# PIC32CM1216LS00032 device description
Architecture: CORTEX-M23; Family: PIC32CM; Series: PIC32CMLS00
Registers are 32-bit, read-write, reset 0x0 unless marked. A register's access mark holds for its fields unless they carry their own. Offsets are from the block's base; [hi:lo] are bit positions; 'fields as' and 'values as' point back to an identical list.

## OSC32KCTRL — 32k Oscillators Control
Instances: OSC32KCTRL 0x40001400
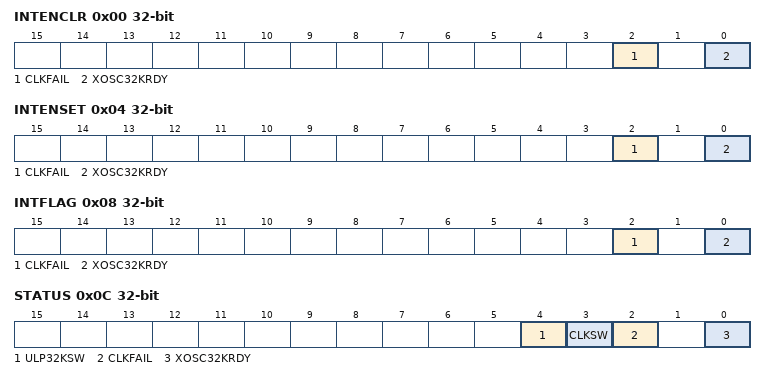
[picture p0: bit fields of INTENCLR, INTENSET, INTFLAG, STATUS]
0x00 INTENCLR (atomic clear) — Interrupt Enable Clear
  [2] CLKFAIL — XOSC32K Clock Failure Detector Interrupt Enable
  [0] XOSC32KRDY — XOSC32K Ready Interrupt Enable
0x04 INTENSET (atomic set) — Interrupt Enable Set
  fields as INTENCLR
0x08 INTFLAG (atomic clear) — Interrupt Flag Status and Clear
  [2] CLKFAIL — XOSC32K Clock Failure Detector
  [0] XOSC32KRDY — XOSC32K Ready
0x0C STATUS ro — Power and Clocks Status
  [4] ULP32KSW — OSCULP32K Clock Switch
  [3] CLKSW — XOSC32K Clock switch
  [2] CLKFAIL — XOSC32K Clock Failure Detector
  [0] XOSC32KRDY — XOSC32K Ready
0x10 RTCCTRL 8-bit — RTC Clock Selection
  [2:0] RTCSEL
    0=ULP1K (1.024kHz from 32kHz internal ULP oscillator); 1=ULP32K (32.768kHz from 32kHz internal ULP oscillator); 4=XOSC1K (1.024kHz from 32.768kHz external crystal oscillator); 5=XOSC32K (32.768kHz from 32.768kHz external crystal oscillator)
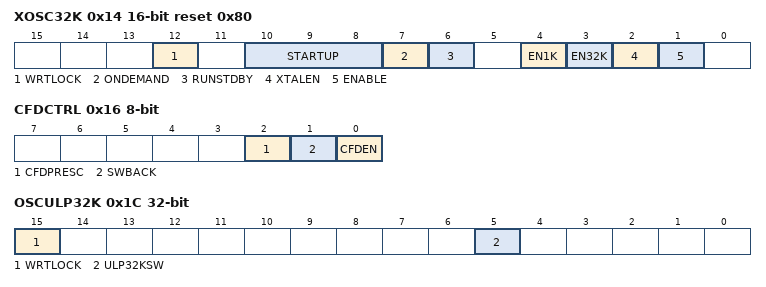
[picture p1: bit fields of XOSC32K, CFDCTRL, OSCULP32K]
0x14 XOSC32K 16-bit reset 0x80 — 32kHz External Crystal Oscillator (XOSC32K) Control
  [12] WRTLOCK — Write Lock
  [10:8] STARTUP — Oscillator Start-Up Time
    0=CYCLE2048 (62.5 ms); 1=CYCLE4096 (125 ms); 2=CYCLE16384 (500 ms); 3=CYCLE32768 (1000 ms); 4=CYCLE65536 (2000 ms); 5=CYCLE131072 (4000 ms); 6=CYCLE262144 (8000 ms)
  [7] ONDEMAND — On Demand Control
  [6] RUNSTDBY — Run in Standby
  [4] EN1K — 1kHz Output Enable
  [3] EN32K — 32kHz Output Enable
  [2] XTALEN — Crystal Oscillator Enable
  [1] ENABLE — Oscillator Enable
0x16 CFDCTRL 8-bit — Clock Failure Detector Control
  [2] CFDPRESC — Clock Failure Detector Prescaler
  [1] SWBACK — Clock Switch Back Enable
  [0] CFDEN — Clock Failure Detector Enable
0x17 EVCTRL 8-bit — Event Control
  [0] CFDEO — Clock Failure Detector Event Output Enable
0x1C OSCULP32K — 32kHz Ultra Low Power Internal Oscillator (OSCULP32K) Control
  [15] WRTLOCK — Write Lock
  [5] ULP32KSW — OSCULP32K Clock Switch Enable

## PM — Power Manager
Instances: PM 0x40000400
0x01 SLEEPCFG 8-bit reset 0x2 — Sleep Configuration
  [2:0] SLEEPMODE
    2=IDLE (CPU, AHBx, and APBx clocks are OFF); 4=STANDBY (ALL clocks are OFF, unless requested by sleepwalking peripheral); 6=OFF (All power domains are powered OFF)
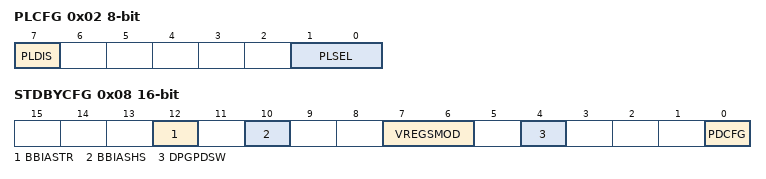
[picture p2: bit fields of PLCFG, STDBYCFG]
0x02 PLCFG 8-bit — Performance Level Configuration
  [7] PLDIS — Performance Level Disable
  [1:0] PLSEL — Performance Level Select
    0=PL0 (Performance Level 0); 2=PL2 (Performance Level 2)
0x03 PWCFG 8-bit — Power Configuration
  [1:0] RAMPSWC — RAM Power Switch Configuration
    0=SIZE0 (SRAM Retention: 64KB (512KB Flash), 32KB (256KB Flash), 16KB (128KB Flash)); 1=SIZE1 (SRAM Retention: 48KB (512KB Flash), 32KB (256KB Flash), 12KB (128KB Flash)); 2=SIZE2 (SRAM Retention: 32KB (512KB Flash), 32KB (256KB Flash), 8KB (128KB Flash)); 3=SIZE3 (SRAM Retention: 16KB (512KB Flash), 16KB (256KB Flash), 4KB (128KB Flash))
0x04 INTENCLR 8-bit (atomic clear) — Interrupt Enable Clear
  [0] PLRDY — Performance Level Interrupt Enable
0x05 INTENSET 8-bit (atomic set) — Interrupt Enable Set
  [0] PLRDY — Performance Level Ready interrupt Enable
0x06 INTFLAG 8-bit (atomic clear) — Interrupt Flag Status and Clear
  [0] PLRDY — Performance Level Ready
0x08 STDBYCFG 16-bit — Standby Configuration
  [12] BBIASTR — Back Bias for Trust RAM
  [10] BBIASHS — Back Bias for SRAM
  [7:6] VREGSMOD — Voltage Regulator Standby mode
    0=AUTO (Automatic mode); 1=PERFORMANCE (Performance oriented); 2=LP (Low Power oriented)
  [4] DPGPDSW — Dynamic Power Gating for PDSW
    0=DISABLED (Dynamic Power Gating disabled); 1=ENABLED (Dynamic Power Gating enabled)
  [0] PDCFG — Power Domain Configuration
    0=DEFAULT (PDSW power domain switching is handled by hardware.); 1=PDSW (PDSW is forced ACTIVE.)
